VERSION ""

NS_ :

BS_:

BU_: Engine Gateway

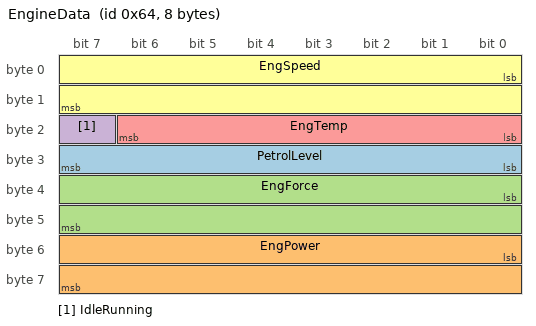
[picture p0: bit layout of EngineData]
BO_ 100 EngineData: 8 Engine
 SG_ PetrolLevel : 24|8@1+ (1,0) [0|255] "l" Gateway
 SG_ EngPower : 48|16@1+ (0.01,0) [0|150] "kW" Gateway
 SG_ EngForce : 32|16@1+ (1,0) [0|0] "N" Gateway
 SG_ IdleRunning : 23|1@1+ (1,0) [0|0] "" Gateway
 SG_ EngTemp : 16|7@1+ (2,-50) [-50|150] "degC" Gateway
 SG_ EngSpeed : 0|16@1+ (1,0) [0|8000] "rpm" Gateway

CM_ "CAN communication matrix for power train electronics
*******************************************************
implemented: turn lights, warning lights, windows";

VAL_ 100 IdleRunning 0 "Running" 1 "Idle" ;
